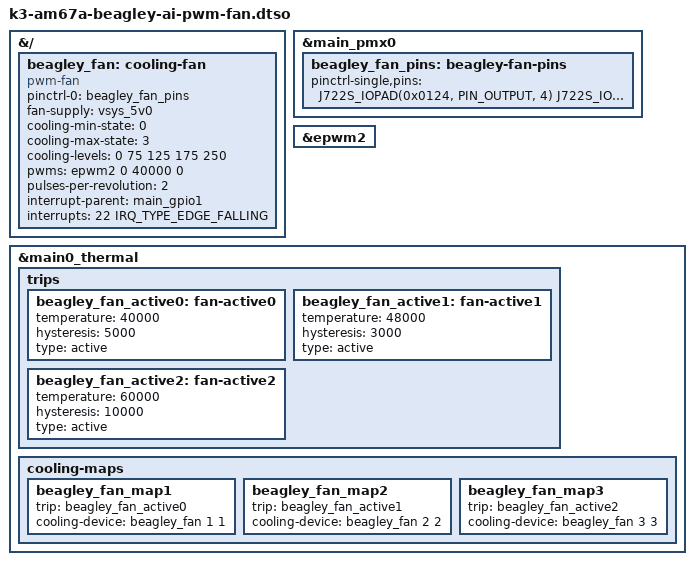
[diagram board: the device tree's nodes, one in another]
// SPDX-License-Identifier: GPL-2.0-only OR MIT
/*
 * BeagleY-AI Raspberry Pi 5-compatible four-pin fan connector.
 *
 * This is kept as an independent overlay so it can be used with the stock
 * BeagleY-AI DTB or composed with display and GPIO accessory overlays.
 */

/dts-v1/;
/plugin/;

#include <dt-bindings/interrupt-controller/irq.h>
#include "k3-pinctrl.h"

&{/} {
	beagley_fan: cooling-fan {
		compatible = "pwm-fan";
		pinctrl-names = "default";
		pinctrl-0 = <&beagley_fan_pins>;
		fan-supply = <&vsys_5v0>;
		#cooling-cells = <2>;
		cooling-min-state = <0>;
		cooling-max-state = <3>;
		cooling-levels = <0 75 125 175 250>;
		pwms = <&epwm2 0 40000 0>;
		pulses-per-revolution = <2>;
		interrupt-parent = <&main_gpio1>;
		interrupts = <22 IRQ_TYPE_EDGE_FALLING>;
		status = "okay";
	};
};

&main_pmx0 {
	beagley_fan_pins: beagley-fan-pins {
		pinctrl-single,pins = <
			J722S_IOPAD(0x0124, PIN_OUTPUT, 4) /* MMC2_SDCD.EHRPWM2_A: FAN_PWM */
			J722S_IOPAD(0x01d0, PIN_INPUT, 7)  /* UART0_CTSn.GPIO1_22: FAN_TACH */
		>;
	};
};

&epwm2 {
	status = "okay";
};

&main0_thermal {
	trips {
		beagley_fan_active0: fan-active0 {
			temperature = <40000>;
			hysteresis = <5000>;
			type = "active";
		};

		beagley_fan_active1: fan-active1 {
			temperature = <48000>;
			hysteresis = <3000>;
			type = "active";
		};

		beagley_fan_active2: fan-active2 {
			temperature = <60000>;
			hysteresis = <10000>;
			type = "active";
		};
	};

	cooling-maps {
		beagley_fan_map1 {
			trip = <&beagley_fan_active0>;
			cooling-device = <&beagley_fan 1 1>;
		};

		beagley_fan_map2 {
			trip = <&beagley_fan_active1>;
			cooling-device = <&beagley_fan 2 2>;
		};

		beagley_fan_map3 {
			trip = <&beagley_fan_active2>;
			cooling-device = <&beagley_fan 3 3>;
		};
	};
};
